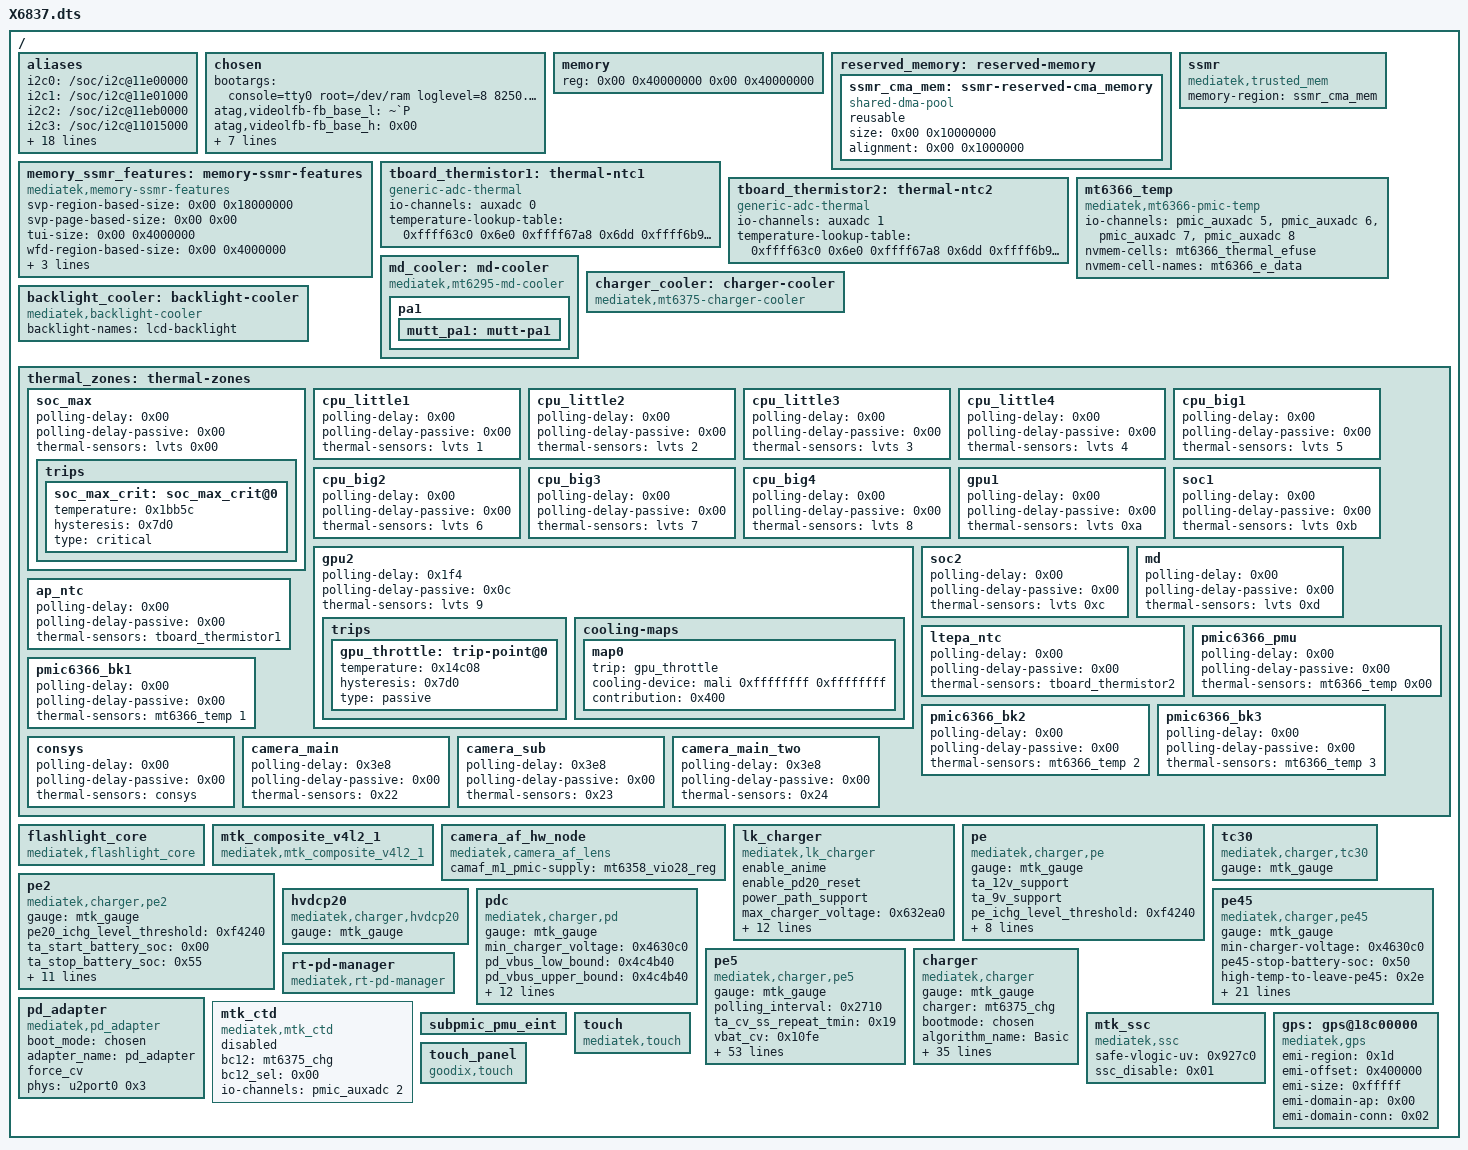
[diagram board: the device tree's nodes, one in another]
// SPDX-License-Identifier: (GPL-2.0 OR MIT)
/*
 * Infinix Hot 40 Pro (MediaTek MT6789 / Helio G99) device tree.
 *
 * Step 1 of bringing the device tree under source control: this is the stock device tree
 * blob decompiled verbatim (dtc -I dtb -O dts), taken from the stock vendor_boot. It builds
 * to a blob that must stay functionally identical to the stock one, which is what every
 * out-of-tree module in mindone/modules binds against (docs/dtb-required-compatibles.txt lists the
 * 91 compatible strings that must survive). Restructuring into labelled nodes and an SoC
 * .dtsi comes later, one verified step at a time.
 */
/dts-v1/;

#include "mt6789.dtsi"
#include "mt6375.dtsi"
#include "X6837-peripherals.dtsi"

/ {
	aliases {
		i2c0 = "/soc/i2c@11e00000";
		i2c1 = "/soc/i2c@11e01000";
		i2c2 = "/soc/i2c@11eb0000";
		i2c3 = "/soc/i2c@11015000";
		i2c4 = "/soc/i2c@11eb1000";
		i2c5 = "/soc/i2c@11017000";
		i2c6 = "/soc/i2c@1101a000";
		i2c7 = "/soc/i2c@11f00000";
		i2c8 = "/soc/i2c@11eb2000";
		i2c9 = "/soc/i2c@11eb3000";
		ovl0 = "/soc/disp_ovl0@14005000";
		ovl3 = "/soc/disp_ovl0_2l@14006000";
		rdma0 = "/soc/disp_rdma0@14007000";
		wdma0 = "/soc/disp_wdma0@14014000";
		dsi0 = "/soc/dsi@14013000";
		color0 = "/soc/disp_color0@14009000";
		ccorr0 = "/soc/disp_ccorr0@1400b000";
		aal0 = "/soc/disp_aal0@1400c000";
		gamma0 = "/soc/disp_gamma0@1400d000";
		dither0 = "/soc/disp_dither0@1400f000";
		postmask0 = "/soc/disp_postmask0@1400e000";
		dsc0 = "/soc/disp_dsc_wrap0@14012000";
	};

	chosen: chosen {
		bootargs = "console=tty0 root=/dev/ram loglevel=8 8250.nr_uarts=4 androidboot.hardware=mt6789 initcall_debug=1 transparent_hugepage=never vmalloc=400M swiotlb=noforce firmware_class.path=/vendor/firmware page_owner=on pelt=8 loop.max_part=7";
		atag,videolfb-fb_base_l = "~`P";
		atag,videolfb-fb_base_h = <0x00>;
		atag,videolfb-islcmfound = <0x01>;
		atag,videolfb-islcm_inited = <0x00>;
		atag,videolfb-fps = <0x1770>;
		atag,videolfb-vramSize = <0x1be0000>;
		atag,videolfb-lcmname = "nt36672e_fhdp_dsi_vdo_60hz_jdi_dphy_drv";
		kaslr-seed = <0x00 0x00>;
	};

	memory {
		device_type = "memory";
		reg = <0x00 0x40000000 0x00 0x40000000>;
	};

	reserved_memory: reserved-memory {
		#address-cells = <0x02>;
		#size-cells = <0x02>;
		ranges;

		ssmr_cma_mem: ssmr-reserved-cma_memory {
			compatible = "shared-dma-pool";
			reusable;
			size = <0x00 0x10000000>;
			alignment = <0x00 0x1000000>;
		};
	};

	memory_ssmr_features: memory-ssmr-features {
		compatible = "mediatek,memory-ssmr-features";
		svp-region-based-size = <0x00 0x18000000>;
		svp-page-based-size = <0x00 0x00>;
		tui-size = <0x00 0x4000000>;
		wfd-region-based-size = <0x00 0x4000000>;
		wfd-page-based-size = <0x00 0x00>;
		prot-region-based-size = <0x00 0x8000000>;
		prot-page-based-size = <0x00 0x00>;
	};

	ssmr {
		compatible = "mediatek,trusted_mem";
		memory-region = <&ssmr_cma_mem>;
	};

	tboard_thermistor1: thermal-ntc1 {
		compatible = "generic-adc-thermal";
		#thermal-sensor-cells = <0x00>;
		io-channels = <&auxadc 0>;
		io-channel-names = "sensor-channel";
		temperature-lookup-table = <0xffff63c0 0x6e0 0xffff67a8 0x6dd 0xffff6b90 0x6da 0xffff6f78 0x6d7 0xffff7360 0x6d3 0xffff7748 0x6d0 0xffff7b30 0x6cc 0xffff7f18 0x6c8 0xffff8300 0x6c3 0xffff86e8 0x6bf 0xffff8ad0 0x6ba 0xffff8eb8 0x6b4 0xffff92a0 0x6af 0xffff9688 0x6a9 0xffff9a70 0x6a3 0xffff9e58 0x69d 0xffffa240 0x696 0xffffa628 0x68f 0xffffaa10 0x688 0xffffadf8 0x680 0xffffb1e0 0x678 0xffffb5c8 0x670 0xffffb9b0 0x667 0xffffbd98 0x65e 0xffffc180 0x654 0xffffc568 0x64a 0xffffc950 0x63f 0xffffcd38 0x634 0xffffd120 0x629 0xffffd508 0x61d 0xffffd8f0 0x611 0xffffdcd8 0x604 0xffffe0c0 0x5f7 0xffffe4a8 0x5ea 0xffffe890 0x5dc 0xffffec78 0x5cd 0xfffff060 0x5be 0xfffff448 0x5af 0xfffff830 0x59f 0xfffffc18 0x58f 0x00 0x57e 0x3e8 0x56d 0x7d0 0x55c 0xbb8 0x54a 0xfa0 0x537 0x1388 0x525 0x1770 0x512 0x1b58 0x4ff 0x1f40 0x4eb 0x2328 0x4d7 0x2710 0x4c3 0x2af8 0x4ae 0x2ee0 0x49a 0x32c8 0x485 0x36b0 0x470 0x3a98 0x45b 0x3e80 0x445 0x4268 0x430 0x4650 0x41a 0x4a38 0x405 0x4e20 0x3ef 0x5208 0x3da 0x55f0 0x3c4 0x59d8 0x3af 0x5dc0 0x399 0x61a8 0x384 0x6590 0x36f 0x6978 0x35a 0x6d60 0x345 0x7148 0x330 0x7530 0x31c 0x7918 0x307 0x7d00 0x2f3 0x80e8 0x2e0 0x84d0 0x2cc 0x88b8 0x2b9 0x8ca0 0x2a6 0x9088 0x293 0x9470 0x281 0x9858 0x26f 0x9c40 0x25d 0xa028 0x24c 0xa410 0x23b 0xa7f8 0x22b 0xabe0 0x21a 0xafc8 0x20b 0xb3b0 0x1fb 0xb798 0x1ec 0xbb80 0x1dd 0xbf68 0x1cf 0xc350 0x1c1 0xc738 0x1b3 0xcb20 0x1a6 0xcf08 0x199 0xd2f0 0x18c 0xd6d8 0x180 0xdac0 0x174 0xdea8 0x168 0xe290 0x15d 0xe678 0x152 0xea60 0x147 0xee48 0x13d 0xf230 0x133 0xf618 0x129 0xfa00 0x120 0xfde8 0x117 0x101d0 0x10e 0x105b8 0x105 0x109a0 0xfd 0x10d88 0xf5 0x11170 0xed 0x11558 0xe6 0x11940 0xde 0x11d28 0xd7 0x12110 0xd1 0x124f8 0xca 0x128e0 0xc4 0x12cc8 0xbd 0x130b0 0xb7 0x13498 0xb2 0x13880 0xac 0x13c68 0xa7 0x14050 0xa1 0x14438 0x9c 0x14820 0x97 0x14c08 0x93 0x14ff0 0x8e 0x153d8 0x8a 0x157c0 0x85 0x15ba8 0x81 0x15f90 0x7d 0x16378 0x79 0x16760 0x76 0x16b48 0x72 0x16f30 0x6f 0x17318 0x6b 0x17700 0x68 0x17ae8 0x65 0x17ed0 0x62 0x182b8 0x5f 0x186a0 0x5c 0x18a88 0x59 0x18e70 0x57 0x19258 0x54 0x19640 0x51 0x19a28 0x4f 0x19e10 0x4d 0x1a1f8 0x4a 0x1a5e0 0x48 0x1a9c8 0x46 0x1adb0 0x44 0x1b198 0x42 0x1b580 0x40 0x1b968 0x3e 0x1bd50 0x3d 0x1c138 0x3b 0x1c520 0x39 0x1c908 0x38 0x1ccf0 0x36 0x1d0d8 0x34 0x1d4c0 0x33 0x1d8a8 0x32 0x1dc90 0x30 0x1e078 0x2f 0x1e460 0x2e 0x1e848 0x2c>;
	};

	tboard_thermistor2: thermal-ntc2 {
		compatible = "generic-adc-thermal";
		#thermal-sensor-cells = <0x00>;
		io-channels = <&auxadc 1>;
		io-channel-names = "sensor-channel";
		temperature-lookup-table = <0xffff63c0 0x6e0 0xffff67a8 0x6dd 0xffff6b90 0x6da 0xffff6f78 0x6d7 0xffff7360 0x6d3 0xffff7748 0x6d0 0xffff7b30 0x6cc 0xffff7f18 0x6c8 0xffff8300 0x6c3 0xffff86e8 0x6bf 0xffff8ad0 0x6ba 0xffff8eb8 0x6b4 0xffff92a0 0x6af 0xffff9688 0x6a9 0xffff9a70 0x6a3 0xffff9e58 0x69d 0xffffa240 0x696 0xffffa628 0x68f 0xffffaa10 0x688 0xffffadf8 0x680 0xffffb1e0 0x678 0xffffb5c8 0x670 0xffffb9b0 0x667 0xffffbd98 0x65e 0xffffc180 0x654 0xffffc568 0x64a 0xffffc950 0x63f 0xffffcd38 0x634 0xffffd120 0x629 0xffffd508 0x61d 0xffffd8f0 0x611 0xffffdcd8 0x604 0xffffe0c0 0x5f7 0xffffe4a8 0x5ea 0xffffe890 0x5dc 0xffffec78 0x5cd 0xfffff060 0x5be 0xfffff448 0x5af 0xfffff830 0x59f 0xfffffc18 0x58f 0x00 0x57e 0x3e8 0x56d 0x7d0 0x55c 0xbb8 0x54a 0xfa0 0x537 0x1388 0x525 0x1770 0x512 0x1b58 0x4ff 0x1f40 0x4eb 0x2328 0x4d7 0x2710 0x4c3 0x2af8 0x4ae 0x2ee0 0x49a 0x32c8 0x485 0x36b0 0x470 0x3a98 0x45b 0x3e80 0x445 0x4268 0x430 0x4650 0x41a 0x4a38 0x405 0x4e20 0x3ef 0x5208 0x3da 0x55f0 0x3c4 0x59d8 0x3af 0x5dc0 0x399 0x61a8 0x384 0x6590 0x36f 0x6978 0x35a 0x6d60 0x345 0x7148 0x330 0x7530 0x31c 0x7918 0x307 0x7d00 0x2f3 0x80e8 0x2e0 0x84d0 0x2cc 0x88b8 0x2b9 0x8ca0 0x2a6 0x9088 0x293 0x9470 0x281 0x9858 0x26f 0x9c40 0x25d 0xa028 0x24c 0xa410 0x23b 0xa7f8 0x22b 0xabe0 0x21a 0xafc8 0x20b 0xb3b0 0x1fb 0xb798 0x1ec 0xbb80 0x1dd 0xbf68 0x1cf 0xc350 0x1c1 0xc738 0x1b3 0xcb20 0x1a6 0xcf08 0x199 0xd2f0 0x18c 0xd6d8 0x180 0xdac0 0x174 0xdea8 0x168 0xe290 0x15d 0xe678 0x152 0xea60 0x147 0xee48 0x13d 0xf230 0x133 0xf618 0x129 0xfa00 0x120 0xfde8 0x117 0x101d0 0x10e 0x105b8 0x105 0x109a0 0xfd 0x10d88 0xf5 0x11170 0xed 0x11558 0xe6 0x11940 0xde 0x11d28 0xd7 0x12110 0xd1 0x124f8 0xca 0x128e0 0xc4 0x12cc8 0xbd 0x130b0 0xb7 0x13498 0xb2 0x13880 0xac 0x13c68 0xa7 0x14050 0xa1 0x14438 0x9c 0x14820 0x97 0x14c08 0x93 0x14ff0 0x8e 0x153d8 0x8a 0x157c0 0x85 0x15ba8 0x81 0x15f90 0x7d 0x16378 0x79 0x16760 0x76 0x16b48 0x72 0x16f30 0x6f 0x17318 0x6b 0x17700 0x68 0x17ae8 0x65 0x17ed0 0x62 0x182b8 0x5f 0x186a0 0x5c 0x18a88 0x59 0x18e70 0x57 0x19258 0x54 0x19640 0x51 0x19a28 0x4f 0x19e10 0x4d 0x1a1f8 0x4a 0x1a5e0 0x48 0x1a9c8 0x46 0x1adb0 0x44 0x1b198 0x42 0x1b580 0x40 0x1b968 0x3e 0x1bd50 0x3d 0x1c138 0x3b 0x1c520 0x39 0x1c908 0x38 0x1ccf0 0x36 0x1d0d8 0x34 0x1d4c0 0x33 0x1d8a8 0x32 0x1dc90 0x30 0x1e078 0x2f 0x1e460 0x2e 0x1e848 0x2c>;
	};

	mt6366_temp: mt6366_temp {
		compatible = "mediatek,mt6366-pmic-temp";
		io-channels = <&pmic_auxadc 5 &pmic_auxadc 6 &pmic_auxadc 7 &pmic_auxadc 8>;
		io-channel-names = "pmic6366_ts1", "pmic6366_ts2", "pmic6366_ts3", "pmic6366_ts4";
		#thermal-sensor-cells = <0x01>;
		nvmem-cells = <&mt6366_thermal_efuse>;
		nvmem-cell-names = "mt6366_e_data";
	};

	md_cooler: md-cooler {
		compatible = "mediatek,mt6295-md-cooler";

		pa1: pa1 {

			mutt_pa1: mutt-pa1 {
				#cooling-cells = <0x02>;
			};
		};
	};

	charger_cooler: charger-cooler {
		compatible = "mediatek,mt6375-charger-cooler";
		#cooling-cells = <0x02>;
	};

	backlight_cooler: backlight-cooler {
		compatible = "mediatek,backlight-cooler";
		backlight-names = "lcd-backlight";
		#cooling-cells = <0x02>;
	};

	thermal_zones: thermal-zones {

		soc_max {
			polling-delay = <0x00>;
			polling-delay-passive = <0x00>;
			thermal-sensors = <&lvts 0x00>;

			trips {

				soc_max_crit: soc_max_crit@0 {
					temperature = <0x1bb5c>;
					hysteresis = <0x7d0>;
					type = "critical";
				};
			};
		};

		cpu_little1 {
			polling-delay = <0x00>;
			polling-delay-passive = <0x00>;
			thermal-sensors = <&lvts 1>;
		};

		cpu_little2 {
			polling-delay = <0x00>;
			polling-delay-passive = <0x00>;
			thermal-sensors = <&lvts 2>;
		};

		cpu_little3 {
			polling-delay = <0x00>;
			polling-delay-passive = <0x00>;
			thermal-sensors = <&lvts 3>;
		};

		cpu_little4 {
			polling-delay = <0x00>;
			polling-delay-passive = <0x00>;
			thermal-sensors = <&lvts 4>;
		};

		cpu_big1 {
			polling-delay = <0x00>;
			polling-delay-passive = <0x00>;
			thermal-sensors = <&lvts 5>;
		};

		cpu_big2 {
			polling-delay = <0x00>;
			polling-delay-passive = <0x00>;
			thermal-sensors = <&lvts 6>;
		};

		cpu_big3 {
			polling-delay = <0x00>;
			polling-delay-passive = <0x00>;
			thermal-sensors = <&lvts 7>;
		};

		cpu_big4 {
			polling-delay = <0x00>;
			polling-delay-passive = <0x00>;
			thermal-sensors = <&lvts 8>;
		};

		gpu2 {
			polling-delay = <0x1f4>;
			polling-delay-passive = <0x0c>;
			thermal-sensors = <&lvts 9>;

			trips {

				gpu_throttle: trip-point@0 {
					temperature = <0x14c08>;
					hysteresis = <0x7d0>;
					type = "passive";
				};
			};

			cooling-maps {

				map0 {
					trip = <&gpu_throttle>;
					cooling-device = <&mali 0xffffffff 0xffffffff>;
					contribution = <0x400>;
				};
			};
		};

		gpu1 {
			polling-delay = <0x00>;
			polling-delay-passive = <0x00>;
			thermal-sensors = <&lvts 0xa>;
		};

		soc1 {
			polling-delay = <0x00>;
			polling-delay-passive = <0x00>;
			thermal-sensors = <&lvts 0xb>;
		};

		soc2 {
			polling-delay = <0x00>;
			polling-delay-passive = <0x00>;
			thermal-sensors = <&lvts 0xc>;
		};

		md {
			polling-delay = <0x00>;
			polling-delay-passive = <0x00>;
			thermal-sensors = <&lvts 0xd>;
		};

		ap_ntc: ap_ntc {
			polling-delay = <0x00>;
			polling-delay-passive = <0x00>;
			thermal-sensors = <&tboard_thermistor1>;
		};

		ltepa_ntc: ltepa_ntc {
			polling-delay = <0x00>;
			polling-delay-passive = <0x00>;
			thermal-sensors = <&tboard_thermistor2>;
		};

		pmic6366_pmu {
			polling-delay = <0x00>;
			polling-delay-passive = <0x00>;
			thermal-sensors = <&mt6366_temp 0x00>;
		};

		pmic6366_bk1 {
			polling-delay = <0x00>;
			polling-delay-passive = <0x00>;
			thermal-sensors = <&mt6366_temp 1>;
		};

		pmic6366_bk2 {
			polling-delay = <0x00>;
			polling-delay-passive = <0x00>;
			thermal-sensors = <&mt6366_temp 2>;
		};

		pmic6366_bk3 {
			polling-delay = <0x00>;
			polling-delay-passive = <0x00>;
			thermal-sensors = <&mt6366_temp 3>;
		};

		consys {
			polling-delay = <0x00>;
			polling-delay-passive = <0x00>;
			thermal-sensors = <&consys>;
		};

		camera_main: camera_main {
			polling-delay = <0x3e8>;
			polling-delay-passive = <0x00>;
			thermal-sensors = <0x22>;
		};

		camera_sub: camera_sub {
			polling-delay = <0x3e8>;
			polling-delay-passive = <0x00>;
			thermal-sensors = <0x23>;
		};

		camera_main_two: camera_main_two {
			polling-delay = <0x3e8>;
			polling-delay-passive = <0x00>;
			thermal-sensors = <0x24>;
		};
	};

	flashlight_core: flashlight_core {
		compatible = "mediatek,flashlight_core";
	};

	mtk_composite_v4l2_1: mtk_composite_v4l2_1 {
		compatible = "mediatek,mtk_composite_v4l2_1";
	};

	camera_af_hw_node: camera_af_hw_node {
		compatible = "mediatek,camera_af_lens";
		camaf_m1_pmic-supply = <&mt6358_vio28_reg>;
		status = "okay";
	};

	lk_charger: lk_charger {
		compatible = "mediatek,lk_charger";
		enable_anime;
		enable_pd20_reset;
		power_path_support;
		max_charger_voltage = <0x632ea0>;
		fast_charge_voltage = <0x2dc6c0>;
		usb_charger_current = <0x7a120>;
		ac_charger_current = <0x1f47d0>;
		ac_charger_input_current = <0x30d400>;
		non_std_ac_charger_current = <0x7a120>;
		charging_host_charger_current = <0x16e360>;
		ta_ac_charger_current = <0x2dc6c0>;
		pd_charger_current = <0x7a120>;
		temp_t4_threshold = <0x32>;
		temp_t3_threshold = <0x2d>;
		temp_t1_threshold = <0x00>;
		enable_check_vsys;
	};

	pe: pe {
		compatible = "mediatek,charger,pe";
		gauge = <&mtk_gauge>;
		ta_12v_support;
		ta_9v_support;
		pe_ichg_level_threshold = <0xf4240>;
		ta_start_battery_soc = <0x00>;
		ta_stop_battery_soc = <0x55>;
		min_charger_voltage = <0x4630c0>;
		ta_ac_12v_input_current = <0x30d400>;
		ta_ac_9v_input_current = <0x30d400>;
		ta_ac_7v_input_current = <0x30d400>;
		pe_charger_current = <0x2dc6c0>;
		vbat_threshold = <0x1036>;
	};

	pe2: pe2 {
		compatible = "mediatek,charger,pe2";
		gauge = <&mtk_gauge>;
		pe20_ichg_level_threshold = <0xf4240>;
		ta_start_battery_soc = <0x00>;
		ta_stop_battery_soc = <0x55>;
		min_charger_voltage = <0x4630c0>;
		cable_imp_threshold = <0x2bb>;
		vbat_cable_imp_threshold = <0x3b8260>;
		sc_input_current = <0x30d400>;
		sc_charger_current = <0x2dc6c0>;
		dcs_input_current = <0x30d400>;
		dcs_chg1_charger_current = <0x16e360>;
		dcs_chg2_charger_current = <0x16e360>;
		dual_polling_ieoc = <0x6ddd0>;
		slave_mivr_diff = <0x186a0>;
		vbat_threshold = <0x1036>;
	};

	tc30: tc30 {
		compatible = "mediatek,charger,tc30";
		gauge = <&mtk_gauge>;
	};

	hvdcp20: hvdcp20 {
		compatible = "mediatek,charger,hvdcp20";
		gauge = <&mtk_gauge>;
	};

	pdc: pdc {
		compatible = "mediatek,charger,pd";
		gauge = <&mtk_gauge>;
		min_charger_voltage = <0x4630c0>;
		pd_vbus_low_bound = <0x4c4b40>;
		pd_vbus_upper_bound = <0x4c4b40>;
		vsys_watt = <0x4c4b40>;
		ibus_err = <0x0e>;
		pd_stop_battery_soc = <0x50>;
		sc_input_current = <0x30d400>;
		sc_charger_current = <0x2dc6c0>;
		dcs_input_current = <0x30d400>;
		dcs_chg1_charger_current = <0x16e360>;
		dcs_chg2_charger_current = <0x16e360>;
		dual_polling_ieoc = <0x6ddd0>;
		slave_mivr_diff = <0x186a0>;
		vbat_threshold = <0x1036>;
		enable-inductor-protect = <0x01>;
	};

	pe45: pe45 {
		compatible = "mediatek,charger,pe45";
		gauge = <&mtk_gauge>;
		min-charger-voltage = <0x4630c0>;
		pe45-stop-battery-soc = <0x50>;
		high-temp-to-leave-pe45 = <0x2e>;
		high-temp-to-enter-pe45 = <0x27>;
		low-temp-to-leave-pe45 = <0x0a>;
		low-temp-to-enter-pe45 = <0x10>;
		ibus-err = <0x0e>;
		pe45-r-cable-1a-lower = <0x1f4>;
		pe45-r-cable-2a-lower = <0x15f>;
		pe45-r-cable-3a-lower = <0xf0>;
		pe45-r-cable-level = <0xc8 0x12c 0x190 0x1f4 0x1f4>;
		pe45-r-cable-voltage = <0x1388 0x157c 0x1770 0x1964 0x1b58>;
		pe45-r-cable-current-limit = <0xbb8 0xbb8 0xbb8 0x9c4 0x898>;
		sc-input-current = <0x30d400>;
		sc-charger-current = <0x2dc6c0>;
		dcs-input-current = <0x30d400>;
		dcs-chg1-charger-current = <0x16e360>;
		dcs-chg2-charger-current = <0x16e360>;
		dual-polling-ieoc = <0x6ddd0>;
		slave-mivr-diff = <0x186a0>;
		vbat-threshold = <0x1036>;
	};

	pe5: pe5 {
		compatible = "mediatek,charger,pe5";
		gauge = <&mtk_gauge>;
		polling_interval = <0x2710>;
		ta_cv_ss_repeat_tmin = <0x19>;
		vbat_cv = <0x10fe>;
		start_soc_min = <0x00>;
		start_soc_max = <0x50>;
		start_vbat_max = <0x10cc>;
		idvchg_term = <0x1f4>;
		idvchg_step = <0x32>;
		ita_level = <0xbb8 0x9c4 0x7d0 0x5dc>;
		rcable_level = <0xfa 0x12c 0x177 0x1f4>;
		ita_level_dual = <0x1388 0xe74 0xd48 0xbb8>;
		rcable_level_dual = <0xe6 0x15e 0x1c2 0x226>;
		idvchg_ss_init = <0x3e8>;
		idvchg_ss_step = <0xfa>;
		idvchg_ss_step1 = <0x64>;
		idvchg_ss_step2 = <0x32>;
		idvchg_ss_step1_vbat = <0xfa0>;
		idvchg_ss_step2_vbat = <0x1068>;
		ta_blanking = <0x190>;
		swchg_aicr = <0x00>;
		swchg_ichg = <0x4b0>;
		swchg_aicr_ss_init = <0x190>;
		swchg_aicr_ss_step = <0xc8>;
		swchg_off_vbat = <0x109a>;
		force_ta_cv_vbat = <0x109a>;
		chg_time_max = <0x1518>;
		tta_level_def = <0x00 0x00 0x00 0x00 0x19 0x32 0x3c 0x46 0x50>;
		tta_curlmt = <0x00 0x00 0x00 0x00 0x00 0x12c 0x258 0x384 0xffffffff>;
		tta_recovery_area = <0x03>;
		tbat_level_def = <0x00 0x00 0x00 0x05 0x19 0x28 0x2b 0x2e 0x32>;
		tbat_curlmt = <0xffffffff 0xffffffff 0xffffffff 0x12c 0x00 0x258 0x384 0x41a 0xffffffff>;
		tbat_recovery_area = <0x03>;
		tdvchg_level_def = <0x00 0x00 0x00 0x05 0x19 0x37 0x3c 0x41 0x46>;
		tdvchg_curlmt = <0xffffffff 0xffffffff 0xffffffff 0x12c 0x00 0x12c 0x258 0x384 0xffffffff>;
		tdvchg_recovery_area = <0x03>;
		tswchg_level_def = <0x00 0x00 0x00 0x05 0x19 0x41 0x46 0x4b 0x50>;
		tswchg_curlmt = <0xffffffff 0xffffffff 0xffffffff 0xc8 0x00 0xc8 0x12c 0x190 0xffffffff>;
		tswchg_recovery_area = <0x03>;
		ifod_threshold = <0xc8>;
		rsw_min = <0x14>;
		ircmp_rbat = <0x28>;
		ircmp_vclamp = <0x00>;
		vta_cap_min = <0x1a90>;
		vta_cap_max = <0x2af8>;
		ita_cap_min = <0x3e8>;
		support_ta = "pca_ta_pps", "pd_adapter";
		allow_not_check_ta_status;
		vbat_threshold = <0x1036>;
	};

	charger: charger {
		compatible = "mediatek,charger";
		gauge = <&mtk_gauge>;
		charger = <&mt6375_chg>;
		bootmode = <&chosen>;
		algorithm_name = "Basic";
		charger_configuration = <0x00>;
		battery_cv = <0x426030>;
		max_charger_voltage = <0x632ea0>;
		min_charger_voltage = <0x4630c0>;
		jeita_temp_above_t4_cv = <0x40b280>;
		jeita_temp_t3_to_t4_cv = <0x40b280>;
		jeita_temp_t2_to_t3_cv = <0x423920>;
		jeita_temp_t1_to_t2_cv = <0x40b280>;
		jeita_temp_t0_to_t1_cv = <0x3da540>;
		jeita_temp_below_t0_cv = <0x3da540>;
		temp_t4_thres = <0x32>;
		temp_t4_thres_minus_x_degree = <0x2f>;
		temp_t3_thres = <0x2d>;
		temp_t3_thres_minus_x_degree = <0x27>;
		temp_t2_thres = <0x0a>;
		temp_t2_thres_plus_x_degree = <0x10>;
		temp_t1_thres = <0x00>;
		temp_t1_thres_plus_x_degree = <0x06>;
		temp_t0_thres = <0x00>;
		temp_t0_thres_plus_x_degree = <0x00>;
		temp_neg_10_thres = <0x00>;
		enable_min_charge_temp;
		min_charge_temp = <0x00>;
		min_charge_temp_plus_x_degree = <0x06>;
		max_charge_temp = <0x32>;
		max_charge_temp_minus_x_degree = <0x2f>;
		usb_charger_current = <0x7a120>;
		ac_charger_current = <0x1f47d0>;
		ac_charger_input_current = <0x30d400>;
		charging_host_charger_current = <0x16e360>;
		enable_dynamic_mivr;
		min_charger_voltage_1 = <0x432380>;
		min_charger_voltage_2 = <0x401640>;
		max_dmivr_charger_current = <0x1b7740>;
		enable_fast_charging_indicator;
	};

	rt-pd-manager {
		compatible = "mediatek,rt-pd-manager";
	};

	pd_adapter: pd_adapter {
		compatible = "mediatek,pd_adapter";
		boot_mode = <&chosen>;
		adapter_name = "pd_adapter";
		force_cv;
		phys = <&u2port0 0x3>;
		phy-names = "usb2-phy";
	};

	mtk_ctd: mtk_ctd {
		compatible = "mediatek,mtk_ctd";
		bc12 = <&mt6375_chg>;
		bc12_sel = <0x00>;
		io-channels = <&pmic_auxadc 2>;
		io-channel-names = "pmic_vbus";
		status = "disabled";
	};

	subpmic_pmu_eint: subpmic_pmu_eint {
	};

	mtk_ssc: mtk_ssc {
		compatible = "mediatek,ssc";
		safe-vlogic-uv = <0x927c0>;
		ssc_disable = <0x01>;
	};

	gps: gps@18c00000 {
		compatible = "mediatek,gps";
		emi-region = <0x1d>;
		emi-offset = <0x400000>;
		emi-size = <0xfffff>;
		emi-domain-ap = <0x00>;
		emi-domain-conn = <0x02>;
	};

	touch: touch {
		compatible = "mediatek,touch";
	};

	touch_panel: touch_panel {
		compatible = "goodix,touch";
	};
};
